# M5531 register map
File version: 1.0
Registers are 32-bit, read-write, reset 0x0 unless marked. A register's access mark holds for its fields unless they carry their own. Offsets are from the block's base; [hi:lo] are bit positions.

## HSUSBD (part 1 of 2) — USBD Register Map
Base 0x40205000
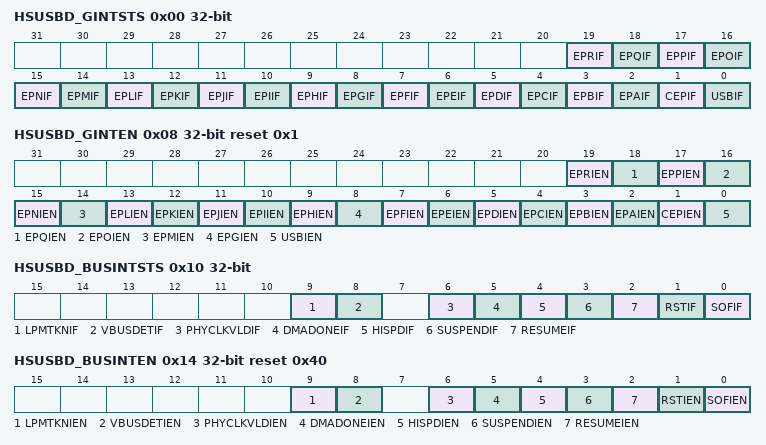
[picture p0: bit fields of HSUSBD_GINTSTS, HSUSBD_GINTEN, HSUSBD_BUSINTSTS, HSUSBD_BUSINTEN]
0x00 HSUSBD_GINTSTS ro — Global Interrupt Status Register
  [all] fields
    0=No interrupt event occurred; 1=The related interrupt event occurred
  [19] EPRIF — Endpoint R Interrupt. When set, the corresponding Endpoint R's interrupt status register should be read to determine the cause of the interrupt.
  [18] EPQIF — Endpoint Q Interrupt. When set, the corresponding Endpoint Q's interrupt status register should be read to determine the cause of the interrupt.
  [17] EPPIF — Endpoint P Interrupt. When set, the corresponding Endpoint P's interrupt status register should be read to determine the cause of the interrupt.
  [16] EPOIF — Endpoint O Interrupt. When set, the corresponding Endpoint O's interrupt status register should be read to determine the cause of the interrupt.
  [15] EPNIF — Endpoint N Interrupt. When set, the corresponding Endpoint N's interrupt status register should be read to determine the cause of the interrupt.
  [14] EPMIF — Endpoint M Interrupt. When set, the corresponding Endpoint M's interrupt status register should be read to determine the cause of the interrupt.
  [13] EPLIF — Endpoint L Interrupt. When set, the corresponding Endpoint L's interrupt status register should be read to determine the cause of the interrupt.
  [12] EPKIF — Endpoint K Interrupt. When set, the corresponding Endpoint K's interrupt status register should be read to determine the cause of the interrupt.
  [11] EPJIF — Endpoint J Interrupt. When set, the corresponding Endpoint J's interrupt status register should be read to determine the cause of the interrupt.
  [10] EPIIF — Endpoint I Interrupt. When set, the corresponding Endpoint I's interrupt status register should be read to determine the cause of the interrupt.
  [9] EPHIF — Endpoint H Interrupt. When set, the corresponding Endpoint H's interrupt status register should be read to determine the cause of the interrupt.
  [8] EPGIF — Endpoint G Interrupt. When set, the corresponding Endpoint G's interrupt status register should be read to determine the cause of the interrupt.
  [7] EPFIF — Endpoint F Interrupt. When set, the corresponding Endpoint F's interrupt status register should be read to determine the cause of the interrupt.
  [6] EPEIF — Endpoint E Interrupt. When set, the corresponding Endpoint E's interrupt status register should be read to determine the cause of the interrupt.
  [5] EPDIF — Endpoint D Interrupt. When set, the corresponding Endpoint D's interrupt status register should be read to determine the cause of the interrupt.
  [4] EPCIF — Endpoint C Interrupt. When set, the corresponding Endpoint C's interrupt status register should be read to determine the cause of the interrupt.
  [3] EPBIF — Endpoint B Interrupt. When set, the corresponding Endpoint B's interrupt status register should be read to determine the cause of the interrupt.
  [2] EPAIF — Endpoint A Interrupt. When set, the corresponding Endpoint A's interrupt status register should be read to determine the cause of the interrupt.
  [1] CEPIF — Control Endpoint Interrupt. This bit conveys the interrupt status for control endpoint. When set, Control-ep's interrupt status register should be read to determine the cause of the interrupt.
  [0] USBIF — USB Interrupt. This bit conveys the interrupt status for USB specific events endpoint. When set, USB interrupt status register should be read to determine the cause of the interrupt.
0x08 HSUSBD_GINTEN reset 0x1 — Global Interrupt Enable Register
  [all] fields
    0=The related interrupt Disabled; 1=The related interrupt Enabled
  [19] EPRIEN — Interrupt Enable Control for Endpoint R. When set, this bit enables a local interrupt to be generated when an interrupt is pending for the endpoint R
  [18] EPQIEN — Interrupt Enable Control for Endpoint Q. When set, this bit enables a local interrupt to be generated when an interrupt is pending for the endpoint Q
  [17] EPPIEN — Interrupt Enable Control for Endpoint P. When set, this bit enables a local interrupt to be generated when an interrupt is pending for the endpoint P
  [16] EPOIEN — Interrupt Enable Control for Endpoint O. When set, this bit enables a local interrupt to be generated when an interrupt is pending for the endpoint O
  [15] EPNIEN — Interrupt Enable Control for Endpoint N. When set, this bit enables a local interrupt to be generated when an interrupt is pending for the endpoint N
  [14] EPMIEN — Interrupt Enable Control for Endpoint M. When set, this bit enables a local interrupt to be generated when an interrupt is pending for the endpoint M
  [13] EPLIEN — Interrupt Enable Control for Endpoint L. When set, this bit enables a local interrupt to be generated when an interrupt is pending for the endpoint L
  [12] EPKIEN — Interrupt Enable Control for Endpoint K. When set, this bit enables a local interrupt to be generated when an interrupt is pending for the endpoint K
  [11] EPJIEN — Interrupt Enable Control for Endpoint J. When set, this bit enables a local interrupt to be generated when an interrupt is pending for the endpoint J
  [10] EPIIEN — Interrupt Enable Control for Endpoint I. When set, this bit enables a local interrupt to be generated when an interrupt is pending for the endpoint I
  [9] EPHIEN — Interrupt Enable Control for Endpoint H. When set, this bit enables a local interrupt to be generated when an interrupt is pending for the endpoint H
  [8] EPGIEN — Interrupt Enable Control for Endpoint G. When set, this bit enables a local interrupt to be generated when an interrupt is pending for the endpoint G
  [7] EPFIEN — Interrupt Enable Control for Endpoint F. When set, this bit enables a local interrupt to be generated when an interrupt is pending for the endpoint F
  [6] EPEIEN — Interrupt Enable Control for Endpoint E. When set, this bit enables a local interrupt to be generated when an interrupt is pending for the endpoint E
  [5] EPDIEN — Interrupt Enable Control for Endpoint D. When set, this bit enables a local interrupt to be generated when an interrupt is pending for the endpoint D
  [4] EPCIEN — Interrupt Enable Control for Endpoint C. When set, this bit enables a local interrupt to be generated when an interrupt is pending for the endpoint C
  [3] EPBIEN — Interrupt Enable Control for Endpoint B. When set, this bit enables a local interrupt to be generated when an interrupt is pending for the endpoint B
  [2] EPAIEN — Interrupt Enable Control for Endpoint A. When set, this bit enables a local interrupt to be generated when an interrupt is pending for the endpoint A.
  [1] CEPIEN — Control Endpoint Interrupt Enable Bit. When set, this bit enables a local interrupt to be generated when an interrupt is pending for the control endpoint.
  [0] USBIEN — USB Interrupt Enable Bit. When set, this bit enables a local interrupt to be generated when a USB event occurs on the bus.
0x10 HSUSBD_BUSINTSTS — USB Bus Interrupt Status Register
  [9] LPMTKNIF — LPM Token Interrupt. Note: Write 1 to clear this bit to 0.
    0=No LPM token has been received from the host; 1=A LPM token has been received from the host
  [8] VBUSDETIF — VBUS Detection Interrupt. Note: Write 1 to clear this bit to 0.
    0=No VBUS is plug-in; 1=VBUS is plug-in
  [6] PHYCLKVLDIF — Usable Clock Interrupt. Note: Write 1 to clear this bit to 0.
    0=Usable clock is not available; 1=Usable clock is available from the transceiver
  [5] DMADONEIF — DMA Completion Interrupt. Note: Write 1 to clear this bit to 0.
    0=No DMA transfer over; 1=DMA transfer is over
  [4] HISPDIF — High-speed Settle Interrupt. Note: Write 1 to clear this bit to 0.
    0=No valid high-speed reset protocol is detected; 1=Valid high-speed reset protocol is over and the device has settled in high-speed
  [3] SUSPENDIF — Suspend Request Interrupt. This bit is set as default and it has to be cleared by writing '1' before the USB reset. This bit is also set when a USB Suspend request is detected from the host. Note: Write 1 to clear this bit to 0.
    0=No USB Suspend request is detected from the host; 1=USB Suspend request is detected from the host
  [2] RESUMEIF — Resume Interrupt. When set, this bit indicates that a device resume has occurred. Note: Write 1 to clear this bit to 0.
    0=No device resume has occurred; 1=Device resume has occurred
  [1] RSTIF — Reset Interrupt. When set, this bit indicates that either the USB root port reset is end. Note: Write 1 to clear this bit to 0.
    0=No USB root port reset is end; 1=USB root port reset is end
  [0] SOFIF — SOF Receive Control Interrupt. This bit indicates when a start-of-frame packet has been received. Note: Write 1 to clear this bit to 0.
    0=No start-of-frame packet has been received; 1=Start-of-frame packet has been received
0x14 HSUSBD_BUSINTEN reset 0x40 — USB Bus Interrupt Enable Register
  [9] LPMTKNIEN — LPM Token Interrupt Enable Bit
    0=The LPM token interrupt Disabled; 1=The LPM token interrupt Enabled
  [8] VBUSDETIEN — VBUS Detection Interrupt Enable Bit. This bit enables the VBUS floating detection interrupt.
    0=VBUS floating detection interrupt Disabled; 1=VBUS floating detection interrupt Enabled
  [6] PHYCLKVLDIEN — Usable Clock Interrupt Enable Bit. This bit enables the usable clock interrupt.
    0=Usable clock interrupt Disabled; 1=Usable clock interrupt Enabled
  [5] DMADONEIEN — DMA Completion Interrupt Enable Bit. This bit enables the DMA completion interrupt
    0=DMA completion interrupt Disabled; 1=DMA completion interrupt Enabled
  [4] HISPDIEN — High-speed Settle Interrupt Enable Bit. This bit enables the high-speed settle interrupt.
    0=High-speed settle interrupt Disabled; 1=High-speed settle interrupt Enabled
  [3] SUSPENDIEN — Suspend Request Interrupt Enable Bit. This bit enables the Suspend interrupt.
    0=Suspend interrupt Disabled; 1=Suspend interrupt Enabled
  [2] RESUMEIEN — Resume Interrupt Enable Bit. This bit enables the Resume interrupt.
    0=Resume interrupt Disabled; 1=Resume interrupt Enabled
  [1] RSTIEN — Reset Interrupt Enable Bit. This bit enables the USB-Reset interrupt.
    0=USB-Reset interrupt Disabled; 1=USB-Reset interrupt Enabled
  [0] SOFIEN — SOF Interrupt Enable Bit. This bit enables the SOF interrupt.
    0=SOF interrupt Disabled; 1=SOF interrupt Enabled
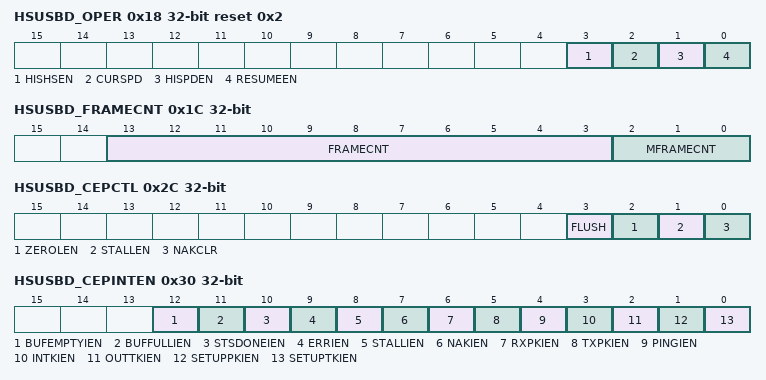
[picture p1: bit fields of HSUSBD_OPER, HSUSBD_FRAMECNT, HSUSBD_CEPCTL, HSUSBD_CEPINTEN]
0x18 HSUSBD_OPER reset 0x2 — USB Operational Register
  [3] HISHSEN — USB High-speed Handshake Enable Bit
    0=The USB device can not start high speed handshake; 1=The USB device can start high speed handshake
  [2] CURSPD — USB Current Speed
    0=The device has settled in full-speed; 1=The USB device controller has settled in high-speed
  [1] HISPDEN — USB High-speed
    0=The USB device controller to suppress the chirp-sequence during reset protocol, thereby allowing the USB device controller to settle in full-speed, even though it is connected to a USB2.0 Host; 1=The USB device controller to initiate a chirp-sequence during reset protocol
  [0] RESUMEEN — Generate Resume
    0=No Resume sequence to be initiated to the host; 1=A Resume sequence to be initiated to the host if device remote wakeup is enabled. This bit is self-clearing
0x1C HSUSBD_FRAMECNT ro — USB Frame Count Register
  [13:3] FRAMECNT — Frame Counter. This field contains the frame count from the most recent start-of-frame packet.
  [2:0] MFRAMECNT — Micro-frame Counter. This field contains the micro-frame number for the frame number in the frame counter field.
0x20 HSUSBD_FADDR — USB Function Address Register
  [6:0] FADDR — USB Function Address. This field contains the current USB address of the device. This field is cleared when a root port reset is detected.
0x24 HSUSBD_TEST — USB Test Mode Register
  [2:0] TESTMODE — Test Mode Selection. Note: This field is cleared when root port reset is detected.
    0=Normal Operation; 1=Test_J; 2=Test_K; 3=Test_SE0_NAK; 4=Test_Packet; 5=Test_Force_Enable
0x28 HSUSBD_CEPDAT — Control-endpoint Data Buffer
  [31:0] DAT — Control-endpoint Data Buffer. Control endpoint data buffer for the buffer transaction (read or write). Note: Only word or byte access are supported.
0x2C HSUSBD_CEPCTL — Control-endpoint Control Register
  [3] FLUSH — CEP-flush Bit
    0=No the packet buffer and its corresponding HSUSBD_CEPDATCNT register to be cleared; 1=The packet buffer and its corresponding HSUSBD_CEPDATCNT register to be cleared. This bit is self-cleaning
  [2] ZEROLEN — Zero Packet Length. This bit is valid for Auto Validation mode only.
    0=No zero length packet to the host during Data stage to an IN token; 1=USB device controller can send a zero length packet to the host during Data stage to an IN token. This bit gets cleared once the zero length data packet is sent. So, the local CPU need not write again to clear this bit
  [1] STALLEN — Stall Enable Bit. When this stall bit is set, the control endpoint sends a stall handshake in response to any in or out token thereafter. This is typically used for response to invalid/unsupported requests. When this bit is being set the NAK clear bit has to be cleared at the same time since the NAK clear bit has highest priority than STALL. It is automatically cleared on receipt of a next setup-token. So, the local CPU need not write again to clear this bit. Note: Only when CPU writes data[1:0] is 2'b10 or 2'b00, this bit can be updated.
    0=No sends a stall handshake in response to any in or out token thereafter; 1=The control endpoint sends a stall handshake in response to any in or out token thereafter
  [0] NAKCLR — No Acknowledge Control. This bit plays a crucial role in any control transfer. Note: Only when CPU writes data[1:0] is 2'b10 or 2'b00, this bit can be updated.
    0=The bit is being cleared by the local CPU by writing zero, the USB device controller will be responding with NAKs for the subsequent status phase. This mechanism holds the host from moving to the next request, until the local CPU is also ready to process the next request; 1=This bit is set to one by the USB device controller, whenever a setup token is received. The local CPU can take its own time to finish off any house-keeping work based on the request and then clear this bit
0x30 HSUSBD_CEPINTEN — Control-endpoint Interrupt Enable
  [12] BUFEMPTYIEN — Buffer Empty Interrupt Enable Bit
    0=The buffer empty interrupt in Control Endpoint Disabled; 1=The buffer empty interrupt in Control Endpoint Enabled
  [11] BUFFULLIEN — Buffer Full Interrupt Enable Bit
    0=The buffer full interrupt in Control Endpoint Disabled; 1=The buffer full interrupt in Control Endpoint Enabled
  [10] STSDONEIEN — Status Completion Interrupt Enable Bit
    0=The Status Completion interrupt in Control Endpoint Disabled; 1=The Status Completion interrupt in Control Endpoint Enabled
  [9] ERRIEN — USB Error Interrupt Enable Bit
    0=The USB Error interrupt in Control Endpoint Disabled; 1=The USB Error interrupt in Control Endpoint Enabled
  [8] STALLIEN — STALL Sent Interrupt Enable Bit
    0=The STALL sent interrupt in Control Endpoint Disabled; 1=The STALL sent interrupt in Control Endpoint Enabled
  [7] NAKIEN — NAK Sent Interrupt Enable Bit
    0=The NAK sent interrupt in Control Endpoint Disabled; 1=The NAK sent interrupt in Control Endpoint Enabled
  [6] RXPKIEN — Data Packet Received Interrupt Enable Bit
    0=The data received interrupt in Control Endpoint Disabled; 1=The data received interrupt in Control Endpoint Enabled
  [5] TXPKIEN — Data Packet Transmitted Interrupt Enable Bit
    0=The data packet transmitted interrupt in Control Endpoint Disabled; 1=The data packet transmitted interrupt in Control Endpoint Enabled
  [4] PINGIEN — Ping Token Interrupt Enable Bit
    0=The ping token interrupt in Control Endpoint Disabled; 1=The ping token interrupt Control Endpoint Enabled
  [3] INTKIEN — In Token Interrupt Enable Bit
    0=The IN token interrupt in Control Endpoint Disabled; 1=The IN token interrupt in Control Endpoint Enabled
  [2] OUTTKIEN — Out Token Interrupt Enable Bit
    0=The OUT token interrupt in Control Endpoint Disabled; 1=The OUT token interrupt in Control Endpoint Enabled
  [1] SETUPPKIEN — Setup Packet Interrupt Enable Bit
    0=The SETUP packet interrupt in Control Endpoint Disabled; 1=The SETUP packet interrupt in Control Endpoint Enabled
  [0] SETUPTKIEN — Setup Token Interrupt Enable Bit
    0=The SETUP token interrupt in Control Endpoint Disabled; 1=The SETUP token interrupt in Control Endpoint Enabled
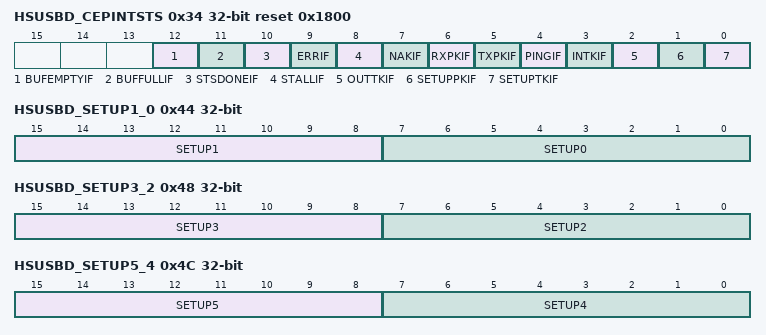
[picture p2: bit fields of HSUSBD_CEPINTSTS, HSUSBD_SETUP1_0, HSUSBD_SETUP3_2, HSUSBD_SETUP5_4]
0x34 HSUSBD_CEPINTSTS reset 0x1800 — Control-endpoint Interrupt Status
  [12] BUFEMPTYIF — Buffer Empty Interrupt. Note: This bit is read-only.
    0=The control-endpoint buffer is not empty; 1=The control-endpoint buffer is empty
  [11] BUFFULLIF — Buffer Full Interrupt. Note: This bit is read-only.
    0=The control-endpoint buffer is not full; 1=The control-endpoint buffer is full
  [10] STSDONEIF — Status Completion Interrupt. Note: Write 1 to clear this bit to 0.
    0=Not a USB transaction has completed successfully; 1=The status stage of a USB transaction has completed successfully
  [9] ERRIF — USB Error Interrupt. Note: Write 1 to clear this bit to 0.
    0=No error had occurred during the transaction; 1=An error had occurred during the transaction
  [8] STALLIF — STALL Sent Interrupt. Note: Write 1 to clear this bit to 0.
    0=Not a stall-token is sent in response to an IN/OUT token; 1=A stall-token is sent in response to an IN/OUT token
  [7] NAKIF — NAK Sent Interrupt. Note: Write 1 to clear this bit to 0.
    0=Not a NAK-token is sent in response to an IN/OUT token; 1=A NAK-token is sent in response to an IN/OUT token
  [6] RXPKIF — Data Packet Received Interrupt. Note: Write 1 to clear this bit to 0.
    0=Not a data packet is successfully received from the host for an OUT-token and an ACK is sent to the host; 1=A data packet is successfully received from the host for an OUT-token and an ACK is sent to the host
  [5] TXPKIF — Data Packet Transmitted Interrupt. Note: Write 1 to clear this bit to 0.
    0=Not a data packet is successfully transmitted to the host in response to an IN-token and an ACK-token is received for the same; 1=A data packet is successfully transmitted to the host in response to an IN-token and an ACK-token is received for the same
  [4] PINGIF — Ping Token Interrupt. Note: Write 1 to clear this bit to 0.
    0=The control-endpoint does not receive a ping token from the host; 1=The control-endpoint receives a ping token from the host
  [3] INTKIF — In Token Interrupt. Note: Write 1 to clear this bit to 0.
    0=The control-endpoint does not receive an IN token from the host; 1=The control-endpoint receives an IN token from the host
  [2] OUTTKIF — Out Token Interrupt. Note: Write 1 to clear this bit to 0.
    0=The control-endpoint does not receive an OUT token from the host; 1=The control-endpoint receives an OUT token from the host
  [1] SETUPPKIF — Setup Packet Interrupt. This bit must be cleared (by writing 1) before the next setup packet can be received. If the bit is not cleared, then the successive setup packets will be overwritten in the setup packet buffer. Note: Write 1 to clear this bit to 0.
    0=Not a Setup packet has been received from the host; 1=A Setup packet has been received from the host
  [0] SETUPTKIF — Setup Token Interrupt. Note: Write 1 to clear this bit to 0.
    0=Not a Setup token is received; 1=A Setup token is received. Writing 1 clears this status bit
0x38 HSUSBD_CEPTXCNT — Control-endpoint In-transfer Data Count
  [7:0] TXCNT — In-transfer Data Count. There is no mode selection for the control endpoint (but it operates like manual mode). The local-CPU has to fill the control-endpoint buffer with the data to be sent for an in-token and to write the count of bytes in this register. When zero is written into this field, a zero length packet is sent to the host. When the count written in the register is more than the MPS, the data sent will be of only MPS.
0x3C HSUSBD_CEPRXCNT ro — Control-endpoint Out-transfer Data Count
  [7:0] RXCNT — Out-transfer Data Count. The USB device controller maintains the count of the data received in case of an out transfer, during the control transfer.
0x40 HSUSBD_CEPDATCNT ro — Control-endpoint Data Count
  [15:0] DATCNT — Control-endpoint Data Count. The USB device controller maintains the count of the data of control-endpoint.
0x44 HSUSBD_SETUP1_0 ro — Setup1 Setup0 Bytes
  [15:8] SETUP1 — Setup Byte 1[15:8]. This register provides byte 1 of the last setup packet received. For a Standard Device Request, the following bRequest Code information is returned.
    0=Get Status; 1=Clear Feature; 3=Set Feature; 5=Set Address; 6=Get Descriptor; 7=Set Descriptor; 8=Get Configuration; 9=Set Configuration; 10=Get Interface; 11=Set Interface; 12=Sync Frame
  [7:0] SETUP0 — Setup Byte 0[7:0]. This register provides byte 0 of the last setup packet received. For a Standard Device Request, the following bmRequestType information is returned. Bit 7 (Direction):
    0=Host to dev........ice. Stand........ard. Dev........ice; 1=Device to h........ost. Cl........ass. Interf........ace; 10=Ven........dor. Endpo........int; 11=Reser........ved. Ot........her
0x48 HSUSBD_SETUP3_2 ro — Setup3 Setup2 Bytes
  [15:8] SETUP3 — Setup Byte 3[15:8]. This register provides byte 3 of the last setup packet received. For a Standard Device Request, the most significant byte of the wValue field is returned.
  [7:0] SETUP2 — Setup Byte 2[7:0]. This register provides byte 2 of the last setup packet received. For a Standard Device Request, the least significant byte of the wValue field is returned.
0x4C HSUSBD_SETUP5_4 ro — Setup5 Setup4 Bytes
  [15:8] SETUP5 — Setup Byte 5[15:8]. This register provides byte 5 of the last setup packet received. For a Standard Device Request, the most significant byte of the wIndex field is returned.
  [7:0] SETUP4 — Setup Byte 4[7:0]. This register provides byte 4 of the last setup packet received. For a Standard Device Request, the least significant byte of the wIndex field is returned.
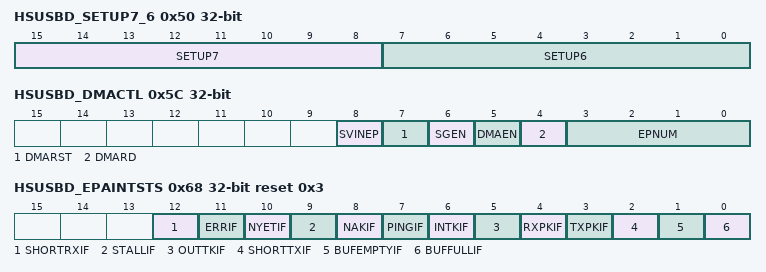
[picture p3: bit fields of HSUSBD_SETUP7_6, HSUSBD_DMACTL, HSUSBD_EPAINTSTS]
0x50 HSUSBD_SETUP7_6 ro — Setup7 Setup6 Bytes
  [15:8] SETUP7 — Setup Byte 7[15:8]. This register provides byte 7 of the last setup packet received. For a Standard Device Request, the most significant byte of the wLength field is returned.
  [7:0] SETUP6 — Setup Byte 6[7:0]. This register provides byte 6 of the last setup packet received. For a Standard Device Request, the least significant byte of the wLength field is returned.
0x54 HSUSBD_CEPBUFSTART — Control Endpoint RAM Start Address Register
  [12:0] SADDR — Control-endpoint Start Address. This is the start-address of the RAM space allocated for the control-endpoint.
0x58 HSUSBD_CEPBUFEND — Control Endpoint RAM End Address Register
  [12:0] EADDR — Control-endpoint End Address. This is the end-address of the RAM space allocated for the control-endpoint.
0x5C HSUSBD_DMACTL — DMA Control Status Register
  [8] SVINEP — Serve IN Endpoint. This bit is used to specify DMA serving endpoint-IN endpoint or OUT endpoint.
    0=DMA serves OUT endpoint; 1=DMA serves IN endpoint
  [7] DMARST — Reset DMA State Machine
    0=No reset the DMA state machine; 1=Reset the DMA state machine
  [6] SGEN — Scatter Gather Function Enable Bit
    0=Scatter gather function Disabled; 1=Scatter gather function Enabled
  [5] DMAEN — DMA Enable Bit
    0=DMA function Disabled; 1=DMA function Enabled
  [4] DMARD — DMA Operation
    0=The operation is a DMA write (read from USB buffer). DMA will check endpoint data available count (HSUSBD_EPxDATCNT) according to EPNUM setting before to perform DMA write operation; 1=The operation is a DMA read (write to USB buffer)
  [3:0] EPNUM — DMA Endpoint Address Bits. Used to define the Endpoint Address
0x60 HSUSBD_DMACNT — DMA Count Register
  [19:0] DMACNT — DMA Transfer Count. The transfer count of the DMA operation to be performed is written to this register.
0x64 HSUSBD_EPADAT — Endpoint A Data Register
  [31:0] EPDAT — Endpoint A~R Data Register. Endpoint A~R data buffer for the buffer transaction (read or write). Note: Only word or byte access are supported.
0x68 HSUSBD_EPAINTSTS reset 0x3 — Endpoint A Interrupt Status Register
  [12] SHORTRXIF — Bulk Out Short Packet Received Interrupt. Note: Write 1 to clear this bit to 0.
    0=No bulk out short packet is received; 1=Received bulk out short packet (including zero length packet)
  [11] ERRIF — ERR Sent Interrupt. Note: Write 1 to clear this bit to 0.
    0=No any error in the transaction; 1=There occurs any error in the transaction
  [10] NYETIF — NYET Sent Interrupt. Note: Write 1 to clear this bit to 0.
    0=The space available in the RAM is sufficient to accommodate the next on coming data packet; 1=The space available in the RAM is not sufficient to accommodate the next on coming data packet
  [9] STALLIF — USB STALL Sent Interrupt. Note: Write 1 to clear this bit to 0.
    0=The last USB packet could be accepted or provided because the endpoint was stalled, and was acknowledged with a STALL; 1=The last USB packet could not be accepted or provided because the endpoint was stalled, and was acknowledged with a STALL
  [8] NAKIF — USB NAK Sent Interrupt. Note: Write 1 to clear this bit to 0.
    0=The last USB IN packet could be provided, and was acknowledged with an ACK; 1=The last USB IN packet could not be provided, and was acknowledged with a NAK
  [7] PINGIF — PING Token Interrupt. Note: Write 1 to clear this bit to 0.
    0=A Data PING token has not been received from the host; 1=A Data PING token has been received from the host
  [6] INTKIF — Data IN Token Interrupt. Note: Write 1 to clear this bit to 0.
    0=Not Data IN token has been received from the host; 1=A Data IN token has been received from the host
  [5] OUTTKIF — Data OUT Token Interrupt. Note: Write 1 to clear this bit to 0.
    0=A Data OUT token has not been received from the host; 1=A Data OUT token has been received from the host. This bit also set by PING token (in high-speed only)
  [4] RXPKIF — Data Packet Received Interrupt. Note: Write 1 to clear this bit to 0.
    0=No data packet is received from the host by the endpoint; 1=A data packet is received from the host by the endpoint
  [3] TXPKIF — Data Packet Transmitted Interrupt. Note: Write 1 to clear this bit to 0.
    0=Not a data packet is transmitted from the endpoint to the host; 1=A data packet is transmitted from the endpoint to the host
  [2] SHORTTXIF — Short Packet Transferred Interrupt. Note: Write 1 to clear this bit to 0.
    0=The length of the last packet was not less than the Maximum Packet Size (EPMPS); 1=The length of the last packet was less than the Maximum Packet Size (EPMPS)
  [1] BUFEMPTYIF — Buffer Empty Interrupt. For an IN endpoint, a buffer is available to the local side for writing up to FIFO full of bytes. Note: This bit is read-only.
    0=The endpoint buffer is not empty. The currently selected buffer has not a count of 0; 1=The endpoint buffer is empty. The currently selected buffer has a count of 0, or no buffer is available on the local side (nothing to read)
  [0] BUFFULLIF — Buffer Full Interrupt. For an IN endpoint, the currently selected buffer is full, or no buffer is available to the local side for writing (no space to write). For an OUT endpoint, there is a buffer available on the local side, and there are FIFO full of bytes available to be read (entire packet is available for reading). Note: This bit is read-only.
    0=The endpoint packet buffer is not full; 1=The endpoint packet buffer is full
